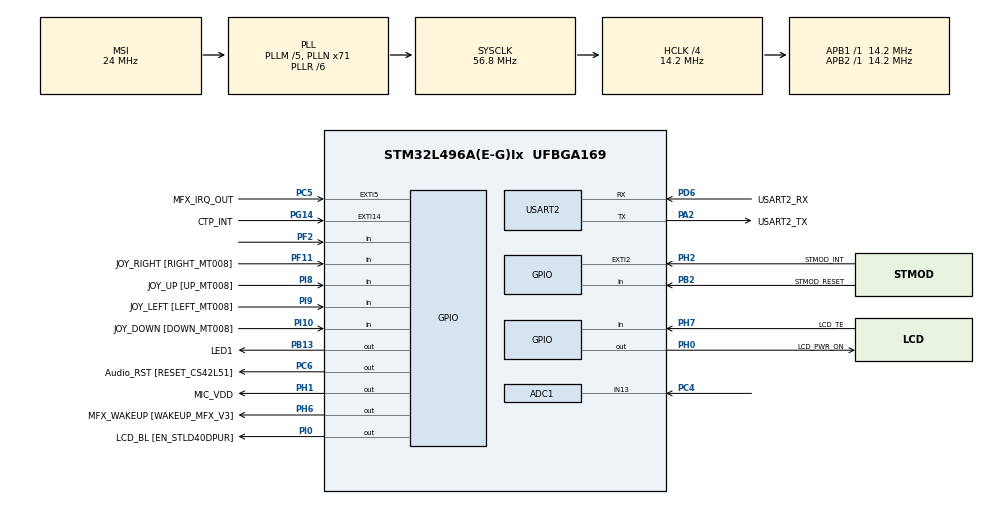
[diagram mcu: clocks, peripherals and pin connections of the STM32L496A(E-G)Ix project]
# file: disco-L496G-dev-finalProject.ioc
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ADC1.Channel-0\#ChannelRegularConversion=ADC_CHANNEL_13
ADC1.NbrOfConversionFlag=1
ADC1.OffsetNumber-0\#ChannelRegularConversion=ADC_OFFSET_NONE
ADC1.Rank-0\#ChannelRegularConversion=1
ADC1.SamplingTime-0\#ChannelRegularConversion=ADC_SAMPLETIME_2CYCLES_5
ADC1.master=1
Mcu.Family=STM32L4
Mcu.Name=STM32L496A(E-G)Ix
Mcu.Package=UFBGA169
NVIC.PriorityGroup=NVIC_PRIORITYGROUP_4
PA0.GPIO_Label=STMOD_PWM
PA0.Signal=SYS_WKUP1
PA1.GPIO_Label=ARD_A4
PA1.Signal=ADCx_IN6
PA10.GPIO_Label=USB_OTGFS_ID
PA10.Signal=USB_OTG_FS_ID
PA11.GPIO_Label=USB_OTGFS_DM
PA11.Signal=USB_OTG_FS_DM
PA12.GPIO_Label=USB_OTGFS_DP
PA12.Signal=USB_OTG_FS_DP
PA13\ (JTMS/SWDIO).GPIO_Label=SWDIO
PA13\ (JTMS/SWDIO).Signal=SYS_JTMS-SWDIO
PA14\ (JTCK/SWCLK).GPIO_Label=SWCLK
PA14\ (JTCK/SWCLK).Signal=SYS_JTCK-SWCLK
PA15\ (JTDI).GPIO_Label=ARD_D10
PA15\ (JTDI).Signal=SPI1_NSS
PA2.GPIO_Label=USART2_TX
PA2.Mode=Asynchronous
PA2.Signal=USART2_TX
PA3.GPIO_Label=QSPI_CLK [MX25R6435FM2IL0_SCLK]
PA3.Signal=QUADSPI_CLK
PA4.GPIO_Label=STMOD_ADC
PA4.Signal=ADCx_IN9
PA5.GPIO_Label=ARD_D13
PA5.Signal=SPI1_SCK
PA6.GPIO_Label=QSPI_BK1_IO3 [MX25R6435FM2IL0_SIO3]
PA6.Signal=QUADSPI_BK1_IO3
PA7.GPIO_Label=QSPI_BK1_IO2 [MX25R6435FM2IL0_SIO2]
PA7.Signal=QUADSPI_BK1_IO2
PA8.GPIO_Label=DCMI_CLK
PA8.Signal=LPTIM2_OUT
PA9.GPIO_Label=USB_OTGFS_VBUS
PA9.Signal=USB_OTG_FS_VBUS
PB0.GPIO_Label=QSPI_BK1_IO1 [MX25R6435FM2IL0_SIO1]
PB0.Signal=QUADSPI_BK1_IO1
PB1.GPIO_Label=QSPI_BK1_IO0 [MX25R6435FM2IL0_SIO0]
PB1.Signal=QUADSPI_BK1_IO0
PB10.GPIO_Label=SAI1_CKA [SLCK_CS42L51]
PB10.Signal=SAI1_SCK_A
PB11.GPIO_Label=QSPI_BK1_NCS [MX25R6435FM2IL0_CS]
PB11.Signal=QUADSPI_BK1_NCS
PB12.GPIO_Label=DFDATIN1
PB12.Signal=S_DATAIN1DFSDM1
PB13.GPIO_Label=LED1
PB13.GPIO_ModeDefaultOutputPP=GPIO_MODE_OUTPUT_OD
PB13.GPIO_PuPd=GPIO_NOPULL
PB13.Signal=GPIO_Output
PB14.GPIO_Label=I2C2_SDA [CS42L51_SDA]
PB14.Signal=I2C2_SDA
PB15.GPIO_Label=SPI2_MOSI
PB15.Signal=SPI2_MOSI
PB2.GPIO_Label=STMOD_RESET
PB2.Signal=GPIO_Input
PB3\ (JTDO/TRACESWO).GPIO_Label=SWO
PB3\ (JTDO/TRACESWO).Signal=SYS_JTDO-SWO
PB4\ (NJTRST).GPIO_Label=ARD_D12
PB4\ (NJTRST).Signal=SPI1_MISO
PB5.GPIO_Label=ARD_D11
PB5.Signal=SPI1_MOSI
PB6.GPIO_Label=USART1_TX
PB6.Signal=USART1_TX
PB7.GPIO_Label=I2C1_SDA
PB7.Signal=I2C1_SDA
PB8.GPIO_Label=I2C1_SCL
PB8.Signal=I2C1_SCL
PB9.GPIO_Label=ARD_D5
PB9.Signal=S_TIM4_CH4
PC0.GPIO_Label=ARD_A5
PC0.Signal=ADCx_IN1
PC1.Signal=ADCx_IN2
PC10.GPIO_Label=uSD_D2
PC10.Signal=SDMMC1_D2
PC11.GPIO_Label=uSD_D3
PC11.Signal=SDMMC1_D3
PC12.GPIO_Label=uSD_CLK
PC12.Signal=SDMMC1_CK
PC13.GPIO_Label=JOY_SEL [Selection_MT008]
PC13.Signal=SYS_WKUP2
PC14-OSC32_IN\ (PC14).Signal=RCC_OSC32_IN
PC15-OSC32_OUT\ (PC15).Signal=RCC_OSC32_OUT
PC2.GPIO_Label=DF_CKOUT
PC2.Signal=S_CKOUTDFSDM1
PC3.GPIO_Label=ARD_A2
PC3.Signal=ADCx_IN4
PC4.Signal=ADCx_IN13
PC5.GPIO_Label=MFX_IRQ_OUT
PC5.Signal=GPXTI5
PC6.GPIO_Label=Audio_RST [RESET_CS42L51]
PC6.Signal=GPIO_Output
PC7.GPIO_Label=DATIN3 [DOUT_MP34DT01TR]
PC7.Signal=S_DATAIN3DFSDM1
PC8.GPIO_Label=uSD_D0
PC8.Signal=SDMMC1_D0
PC9.GPIO_Label=uSD_D1
PC9.Signal=SDMMC1_D1
PD0.GPIO_Label=D2 [D2_ IS66WV51216EBLL]
PD0.Signal=FMC_D2_DA2
PD1.GPIO_Label=D3 [D3_IS66WV51216EBLL]
PD1.Signal=FMC_D3_DA3
PD10.GPIO_Label=D15 [D15_IS66WV51216EBLL]
PD10.Signal=FMC_D15_DA15
PD11.GPIO_Label=PSRAM_A16 [A16_IS66WV51216EBLL]
PD11.Signal=FMC_A16_CLE
PD12.GPIO_Label=PSRAM_A17 [A17_IS66WV51216EBLL]
PD12.Signal=FMC_A17_ALE
PD13.GPIO_Label=PSRAM_A18_LCD_RS [A18_IS66WV51216EBLL]
PD13.Signal=FMC_A18
PD14.GPIO_Label=D0 [D0_IS66WV51216EBLL]
PD14.Signal=FMC_D0_DA0
PD15.GPIO_Label=D1 [D1_IS66WV51216EBLL]
PD15.Signal=FMC_D1_DA1
PD2.GPIO_Label=uSD_CMD
PD2.Signal=SDMMC1_CMD
PD4.GPIO_Label=OE [OE_IS66WV51216EBLL]
PD4.Signal=FMC_NOE
PD5.GPIO_Label=WE [WE_IS66WV51216EBLL]
PD5.Signal=FMC_NWE
PD6.GPIO_Label=USART2_RX
PD6.Mode=Asynchronous
PD6.Signal=USART2_RX
PD7.GPIO_Label=LCD_NE
PD7.Signal=FMC_NE1
PD8.GPIO_Label=D13 [D13_IS66WV51216EBLL]
PD8.Signal=FMC_D13_DA13
PD9.GPIO_Label=D14 [D14_IS66WV51216EBLL]
PD9.Signal=FMC_D14_DA14
PE0.GPIO_Label=PSRAM_NBL0 [LB_IS66WV51216EBLL]
PE0.Signal=FMC_NBL0
PE1.GPIO_Label=PSRAM_NBL1 [UB_IS66WV51216EBLL]
PE1.Signal=FMC_NBL1
PE10.GPIO_Label=D7 [D7_IS66WV51216EBLL]
PE10.Signal=FMC_D7_DA7
PE11.GPIO_Label=D8  [D8_IS66WV51216EBLL]
PE11.Signal=FMC_D8_DA8
PE12.GPIO_Label=D9 [D9_IS66WV51216EBLL]
PE12.Signal=FMC_D9_DA9
PE13.GPIO_Label=D10 [D10_IS66WV51216EBLL]
PE13.Signal=FMC_D10_DA10
PE14.GPIO_Label=D11 [D11_IS66WV51216EBLL]
PE14.Signal=FMC_D11_DA11
PE15.GPIO_Label=D12 [D12_IS66WV51216EBLL]
PE15.Signal=FMC_D12_DA12
PE2.GPIO_Label=SAI1_MCKA [MCLK_CS42L51]
PE2.Signal=SAI1_MCLK_A
PE3.GPIO_Label=SAI1_SDB [SDOUT_CS42L51]
PE3.Signal=SAI1_SD_B
PE4.GPIO_Label=SAI1_FSA [LRCK_CS42L51]]
PE4.Signal=SAI1_FS_A
PE5.GPIO_Label=DCMI_D6
PE5.Signal=DCMI_D6
PE6.GPIO_Label=SAI1_SDA [SDIN_CS42L51]
PE6.Signal=SAI1_SD_A
PE7.GPIO_Label=D4 [D4_IS66WV51216EBLL]
PE7.Signal=FMC_D4_DA4
PE8.GPIO_Label=D5 [D5_IS66WV51216EBLL]
PE8.Signal=FMC_D5_DA5
PE9.GPIO_Label=D6 [D6_IS66WV51216EBLL]
PE9.Signal=FMC_D6_DA6
PF0.GPIO_Label=PSRAM_A0 [A0_IS66WV51216EBLL]
PF0.Signal=FMC_A0
PF1.GPIO_Label=PSRAM_A1 [A1_IS66WV51216EBLL]
PF1.Signal=FMC_A1
PF10.GPIO_Label=ARD_A3
PF10.Signal=ADC3_IN13
PF11.GPIO_Label=JOY_RIGHT [RIGHT_MT008]
PF11.GPIO_PuPd=GPIO_PULLDOWN
PF11.Signal=GPIO_Input
PF12.GPIO_Label=PSRAM_A6 [A6_IS66WV51216EBLL]
PF12.Signal=FMC_A6
PF13.GPIO_Label=PSRAM_A7 [A7_IS66WV51216EBLL]
PF13.Signal=FMC_A7
PF14.GPIO_Label=PSRAM_A8 [A8_IS66WV51216EBLL]
PF14.Signal=FMC_A8
PF15.GPIO_Label=PSRAM_A9 [A9_IS66WV51216EBLL]
PF15.Signal=FMC_A9
PF2.Signal=GPIO_Input
PF3.GPIO_Label=PSRAM_A3 [A3_IS66WV51216EBLL]
PF3.Signal=FMC_A3
PF4.GPIO_Label=PSRAM_A4 [A4_IS66WV51216EBLL]
PF4.Signal=FMC_A4
PF5.GPIO_Label=PSRAM_A5 [A5_IS66WV51216EBLL]
PF5.Signal=FMC_A5
PG0.GPIO_Label=PSRAM_A10 [A10_IS66WV51216EBLL]
PG0.Signal=FMC_A10
PG1.GPIO_Label=PSRAM_A11 [A11_IS66WV51216EBLL]
PG1.Signal=FMC_A11
PG10.GPIO_Label=UART1_RX [STMOD+_UART]
PG10.Signal=USART1_RX
PG11.GPIO_Label=UART1_CTS [STMOD+_UART]
PG11.Signal=USART1_CTS
PG12.GPIO_Label=UART1_RTS [STMOD+_UART]
PG12.Signal=USART1_RTS
PG14.GPIO_Label=CTP_INT
PG14.Signal=GPXTI14
PG2.GPIO_Label=PSRAM_A12 [A12_IS66WV51216EBLL]
PG2.Signal=FMC_A12
PG3.GPIO_Label=PSRAM_A13 [A13_IS66WV51216EBLL]
PG3.Signal=FMC_A13
PG4.GPIO_Label=PSRAM_A14 [A14_IS66WV51216EBLL]
PG4.Signal=FMC_A14
PG5.GPIO_Label=PSRAM_A15 [A15_IS66WV51216EBLL]
PG5.Signal=FMC_A15
PG7.GPIO_Label=ARD_D1
PG7.Signal=LPUART1_TX
PG8.GPIO_Label=ARD_D0
PG8.Signal=LPUART1_RX
PG9.GPIO_Label=PSRAM_NE [CS1_IS66WV51216EBLL]
PG9.Signal=FMC_NE2
PH0-OSC_IN\ (PH0).GPIO_Label=LCD_PWR_ON
PH0-OSC_IN\ (PH0).Signal=GPIO_Output
PH1-OSC_OUT\ (PH1).GPIO_Label=MIC_VDD
PH1-OSC_OUT\ (PH1).Signal=GPIO_Output
PH10.GPIO_Label=DCMI_D1
PH10.Signal=DCMI_D1
PH11.GPIO_Label=DCMI_D2
PH11.Signal=DCMI_D2
PH12.GPIO_Label=DCMI_D3
PH12.Signal=DCMI_D3
PH13.GPIO_Label=ARD_D9
PH13.Signal=TIM8_CH1N
PH14.GPIO_Label=DCMI_D4
PH14.Signal=DCMI_D4
PH15.GPIO_Label=ARD_D3
PH15.Signal=TIM8_CH3N
PH2.GPIO_Label=STMOD_INT
PH2.Signal=GPXTI2
PH4.GPIO_Label=I2C2_SCL [SCL_CS42L51]
PH4.Signal=I2C2_SCL
PH5.GPIO_Label=DCMI_PIXCK
PH5.Signal=DCMI_PIXCLK
PH6.GPIO_Label=MFX_WAKEUP [WAKEUP_MFX_V3]
PH6.Signal=GPIO_Output
PH7.GPIO_Label=LCD_TE
PH7.Signal=GPIO_Input
PH8.GPIO_Label=DCMI_HSYNC
PH8.Signal=DCMI_HSYNC
PH9.GPIO_Label=DCMI_D0
PH9.Signal=DCMI_D0
PI0.GPIO_Label=LCD_BL [EN_STLD40DPUR]
PI0.Signal=GPIO_Output
PI1.GPIO_Label=SPI2_CLK [STMOD+_SPI]
PI1.Signal=SPI2_SCK
PI10.GPIO_Label=JOY_DOWN [DOWN_MT008]
PI10.GPIO_PuPd=GPIO_PULLDOWN
PI10.Signal=GPIO_Input
PI2.GPIO_Label=SPI2_MISO [STMOD+_SPI]
PI2.Signal=SPI2_MISO
PI4.GPIO_Label=DCMI_D5
PI4.Signal=DCMI_D5
PI5.GPIO_Label=DCMI_VSYNC
PI5.Signal=DCMI_VSYNC
PI6.GPIO_Label=ARD_D6
PI6.Signal=S_TIM8_CH2
PI7.GPIO_Label=DCMI_D7
PI7.Signal=DCMI_D7
PI8.GPIO_Label=JOY_UP [UP_MT008]
PI8.GPIO_PuPd=GPIO_PULLDOWN
PI8.Signal=GPIO_Input
PI9.GPIO_Label=JOY_LEFT [LEFT_MT008]
PI9.GPIO_PuPd=GPIO_PULLDOWN
PI9.Signal=GPIO_Input
ProjectManager.HeapSize=0x200
ProjectManager.StackSize=0x400
ProjectManager.TargetToolchain=STM32CubeIDE
RCC.ADCFreq_Value=48000000
RCC.AHBCLKDivider=RCC_SYSCLK_DIV4
RCC.AHBFreq_Value=14200000
RCC.APB1Freq_Value=14200000
RCC.APB1TimFreq_Value=14200000
RCC.APB2Freq_Value=14200000
RCC.APB2TimFreq_Value=14200000
RCC.CortexFreq_Value=14200000
RCC.HCLKFreq_Value=14200000
RCC.HSE_VALUE=8000000
RCC.HSI48_VALUE=48000000
RCC.HSI_VALUE=16000000
RCC.LSE_VALUE=32768
RCC.MSIClockRange=RCC_MSIRANGE_9
RCC.MSI_VALUE=24000000
RCC.PLLM=5
RCC.PLLN=71
RCC.PLLR=RCC_PLLR_DIV6
RCC.PLLSAI1N=20
RCC.SYSCLKFreq_VALUE=56800000
RCC.SYSCLKSource=RCC_SYSCLKSOURCE_PLLCLK
RCC.USBFreq_Value=48000000
RCC.VCOOutputFreq_Value=340800000
SH.ADCx_IN1.0=ADC2_IN1
SH.ADCx_IN13.0=ADC1_IN13,IN13-Single-Ended
SH.ADCx_IN2.0=ADC2_IN2
SH.ADCx_IN4.0=ADC1_IN4
SH.ADCx_IN6.0=ADC2_IN6
SH.ADCx_IN9.0=ADC2_IN9
SH.FMC_A0.0=FMC_A0
SH.FMC_A1.0=FMC_A1
SH.FMC_A10.0=FMC_A10
SH.FMC_A11.0=FMC_A11
SH.FMC_A12.0=FMC_A12
SH.FMC_A13.0=FMC_A13
SH.FMC_A14.0=FMC_A14
SH.FMC_A15.0=FMC_A15
SH.FMC_A16_CLE.0=FMC_A16
SH.FMC_A17_ALE.0=FMC_A17
SH.FMC_A18.0=FMC_A18
SH.FMC_A3.0=FMC_A3
SH.FMC_A4.0=FMC_A4
SH.FMC_A5.0=FMC_A5
SH.FMC_A6.0=FMC_A6
SH.FMC_A7.0=FMC_A7
SH.FMC_A8.0=FMC_A8
SH.FMC_A9.0=FMC_A9
SH.FMC_D0_DA0.0=FMC_D0
SH.FMC_D10_DA10.0=FMC_D10
SH.FMC_D11_DA11.0=FMC_D11
SH.FMC_D12_DA12.0=FMC_D12
SH.FMC_D13_DA13.0=FMC_D13
SH.FMC_D14_DA14.0=FMC_D14
SH.FMC_D15_DA15.0=FMC_D15
SH.FMC_D1_DA1.0=FMC_D1
SH.FMC_D2_DA2.0=FMC_D2
SH.FMC_D3_DA3.0=FMC_D3
SH.FMC_D4_DA4.0=FMC_D4
SH.FMC_D5_DA5.0=FMC_D5
SH.FMC_D6_DA6.0=FMC_D6
SH.FMC_D7_DA7.0=FMC_D7
SH.FMC_D8_DA8.0=FMC_D8
SH.FMC_D9_DA9.0=FMC_D9
SH.FMC_NBL0.0=FMC_NBL0
SH.FMC_NBL1.0=FMC_NBL1
SH.FMC_NOE.0=FMC_NOE
SH.FMC_NWE.0=FMC_NWE
SH.S_CKOUTDFSDM1.0=DFSDM1_CKOUT
SH.S_DATAIN1DFSDM1.0=DFSDM1_DATIN1
SH.S_DATAIN3DFSDM1.0=DFSDM1_DATIN3
SH.S_TIM4_CH4.0=TIM4_CH4
SH.S_TIM8_CH2.0=TIM8_CH2
USART2.VirtualMode-Asynchronous=VM_ASYNC
board=STM32L496G-DISCO

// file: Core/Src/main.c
/* USER CODE BEGIN Header */
/**
  ******************************************************************************
  * @file           : main.c
  * @brief          : Main program body
  ******************************************************************************
  * @attention
  *
  * Copyright (c) 2022 STMicroelectronics.
  * All rights reserved.
  *
  * This software is licensed under terms that can be found in the LICENSE file
  * in the root directory of this software component.
  * If no LICENSE file comes with this software, it is provided AS-IS.
  *
  ******************************************************************************
  */
/* USER CODE END Header */
#include "main.h"
#include "stdio.h"

ADC_HandleTypeDef hadc1;

UART_HandleTypeDef huart2;

void SystemClock_Config(void);
static void MX_GPIO_Init(void);
static void MX_USART2_UART_Init(void);
static void MX_ADC1_Init(void);

/* USER CODE BEGIN 0 */

int _write(int file, char *ptr, int len)
{

	HAL_UART_Transmit(&huart2, (uint8_t*)ptr, len, HAL_MAX_DELAY);
	return len;
}

/* USER CODE END 0 */

int main(void)
{

  /* MCU Configuration--------------------------------------------------------*/

  /* Reset of all peripherals, Initializes the Flash interface and the Systick. */
  HAL_Init();

  /* Configure the system clock */
  SystemClock_Config();

  /* Initialize all configured peripherals */
  MX_GPIO_Init();
  MX_USART2_UART_Init();
  MX_ADC1_Init();

  /* Infinite loop */
  /* USER CODE BEGIN WHILE */
  while (1)
  {

	 //printf("working");

	  // c
	  HAL_ADC_Start(&hadc1);
	  HAL_ADC_PollForConversion(&hadc1, HAL_MAX_DELAY);

	  uint32_t value= HAL_ADC_GetValue(&hadc1);
	  float voltage = (5.0 * value) / (4096.0);
	  printf("Voltage Value Read From Knob: %f \r\n", voltage);

    /* USER CODE END WHILE */

  }
}

void SystemClock_Config(void)
{
  RCC_OscInitTypeDef RCC_OscInitStruct = {0};
  RCC_ClkInitTypeDef RCC_ClkInitStruct = {0};

  /** Configure the main internal regulator output voltage
  */
  if (HAL_PWREx_ControlVoltageScaling(PWR_REGULATOR_VOLTAGE_SCALE1) != HAL_OK)
  {
    Error_Handler();
  }

  /** Initializes the RCC Oscillators according to the specified parameters
  * in the RCC_OscInitTypeDef structure.
  */
  RCC_OscInitStruct.OscillatorType = RCC_OSCILLATORTYPE_MSI;
  RCC_OscInitStruct.MSIState = RCC_MSI_ON;
  RCC_OscInitStruct.MSICalibrationValue = 0;
  RCC_OscInitStruct.MSIClockRange = RCC_MSIRANGE_9;
  RCC_OscInitStruct.PLL.PLLState = RCC_PLL_ON;
  RCC_OscInitStruct.PLL.PLLSource = RCC_PLLSOURCE_MSI;
  RCC_OscInitStruct.PLL.PLLM = 5;
  RCC_OscInitStruct.PLL.PLLN = 71;
  RCC_OscInitStruct.PLL.PLLP = RCC_PLLP_DIV2;
  RCC_OscInitStruct.PLL.PLLQ = RCC_PLLQ_DIV2;
  RCC_OscInitStruct.PLL.PLLR = RCC_PLLR_DIV6;
  if (HAL_RCC_OscConfig(&RCC_OscInitStruct) != HAL_OK)
  {
    Error_Handler();
  }

  /** Initializes the CPU, AHB and APB buses clocks
  */
  RCC_ClkInitStruct.ClockType = RCC_CLOCKTYPE_HCLK|RCC_CLOCKTYPE_SYSCLK
                              |RCC_CLOCKTYPE_PCLK1|RCC_CLOCKTYPE_PCLK2;
  RCC_ClkInitStruct.SYSCLKSource = RCC_SYSCLKSOURCE_PLLCLK;
  RCC_ClkInitStruct.AHBCLKDivider = RCC_SYSCLK_DIV4;
  RCC_ClkInitStruct.APB1CLKDivider = RCC_HCLK_DIV1;
  RCC_ClkInitStruct.APB2CLKDivider = RCC_HCLK_DIV1;

  if (HAL_RCC_ClockConfig(&RCC_ClkInitStruct, FLASH_LATENCY_0) != HAL_OK)
  {
    Error_Handler();
  }
}

static void MX_ADC1_Init(void)
{

  ADC_MultiModeTypeDef multimode = {0};
  ADC_ChannelConfTypeDef sConfig = {0};

  /** Common config
  */
  hadc1.Instance = ADC1;
  hadc1.Init.ClockPrescaler = ADC_CLOCK_ASYNC_DIV1;
  hadc1.Init.Resolution = ADC_RESOLUTION_12B;
  hadc1.Init.DataAlign = ADC_DATAALIGN_RIGHT;
  hadc1.Init.ScanConvMode = ADC_SCAN_DISABLE;
  hadc1.Init.EOCSelection = ADC_EOC_SINGLE_CONV;
  hadc1.Init.LowPowerAutoWait = DISABLE;
  hadc1.Init.ContinuousConvMode = DISABLE;
  hadc1.Init.NbrOfConversion = 1;
  hadc1.Init.DiscontinuousConvMode = DISABLE;
  hadc1.Init.ExternalTrigConv = ADC_SOFTWARE_START;
  hadc1.Init.ExternalTrigConvEdge = ADC_EXTERNALTRIGCONVEDGE_NONE;
  hadc1.Init.DMAContinuousRequests = DISABLE;
  hadc1.Init.Overrun = ADC_OVR_DATA_PRESERVED;
  hadc1.Init.OversamplingMode = DISABLE;
  if (HAL_ADC_Init(&hadc1) != HAL_OK)
  {
    Error_Handler();
  }

  /** Configure the ADC multi-mode
  */
  multimode.Mode = ADC_MODE_INDEPENDENT;
  if (HAL_ADCEx_MultiModeConfigChannel(&hadc1, &multimode) != HAL_OK)
  {
    Error_Handler();
  }

  /** Configure Regular Channel
  */
  sConfig.Channel = ADC_CHANNEL_13;
  sConfig.Rank = ADC_REGULAR_RANK_1;
  sConfig.SamplingTime = ADC_SAMPLETIME_2CYCLES_5;
  sConfig.SingleDiff = ADC_SINGLE_ENDED;
  sConfig.OffsetNumber = ADC_OFFSET_NONE;
  sConfig.Offset = 0;
  if (HAL_ADC_ConfigChannel(&hadc1, &sConfig) != HAL_OK)
  {
    Error_Handler();
  }

}

static void MX_USART2_UART_Init(void)
{

  huart2.Instance = USART2;
  huart2.Init.BaudRate = 115200;
  huart2.Init.WordLength = UART_WORDLENGTH_8B;
  huart2.Init.StopBits = UART_STOPBITS_1;
  huart2.Init.Parity = UART_PARITY_NONE;
  huart2.Init.Mode = UART_MODE_TX_RX;
  huart2.Init.HwFlowCtl = UART_HWCONTROL_NONE;
  huart2.Init.OverSampling = UART_OVERSAMPLING_16;
  huart2.Init.OneBitSampling = UART_ONE_BIT_SAMPLE_DISABLE;
  huart2.AdvancedInit.AdvFeatureInit = UART_ADVFEATURE_NO_INIT;
  if (HAL_UART_Init(&huart2) != HAL_OK)
  {
    Error_Handler();
  }

}

static void MX_GPIO_Init(void)
{
  GPIO_InitTypeDef GPIO_InitStruct = {0};

  /* GPIO Ports Clock Enable */
  __HAL_RCC_GPIOI_CLK_ENABLE();
  __HAL_RCC_GPIOH_CLK_ENABLE();
  __HAL_RCC_GPIOE_CLK_ENABLE();
  __HAL_RCC_GPIOB_CLK_ENABLE();
  __HAL_RCC_GPIOA_CLK_ENABLE();
  __HAL_RCC_GPIOG_CLK_ENABLE();
  HAL_PWREx_EnableVddIO2();
  __HAL_RCC_GPIOD_CLK_ENABLE();
  __HAL_RCC_GPIOC_CLK_ENABLE();
  __HAL_RCC_GPIOF_CLK_ENABLE();

  /*Configure GPIO pin Output Level */
  HAL_GPIO_WritePin(LCD_BL_GPIO_Port, LCD_BL_Pin, GPIO_PIN_RESET);

  /*Configure GPIO pin Output Level */
  HAL_GPIO_WritePin(GPIOH, MFX_WAKEUP_Pin|LCD_PWR_ON_Pin|MIC_VDD_Pin, GPIO_PIN_RESET);

  /*Configure GPIO pin Output Level */
  HAL_GPIO_WritePin(Audio_RST_GPIO_Port, Audio_RST_Pin, GPIO_PIN_RESET);

  /*Configure GPIO pin Output Level */
  HAL_GPIO_WritePin(LED1_GPIO_Port, LED1_Pin, GPIO_PIN_RESET);

  /*Configure GPIO pins : JOY_DOWN_Pin JOY_LEFT_Pin JOY_UP_Pin */
  GPIO_InitStruct.Pin = JOY_DOWN_Pin|JOY_LEFT_Pin|JOY_UP_Pin;
  GPIO_InitStruct.Mode = GPIO_MODE_INPUT;
  GPIO_InitStruct.Pull = GPIO_PULLDOWN;
  HAL_GPIO_Init(GPIOI, &GPIO_InitStruct);

  /*Configure GPIO pin : STMOD_INT_Pin */
  GPIO_InitStruct.Pin = STMOD_INT_Pin;
  GPIO_InitStruct.Mode = GPIO_MODE_IT_RISING;
  GPIO_InitStruct.Pull = GPIO_NOPULL;
  HAL_GPIO_Init(STMOD_INT_GPIO_Port, &GPIO_InitStruct);

  /*Configure GPIO pins : PSRAM_NBL0_Pin PSRAM_NBL1_Pin D7_Pin D6_Pin
                           D12_Pin D5_Pin D11_Pin D4_Pin
                           D10_Pin D9_Pin D8_Pin */
  GPIO_InitStruct.Pin = PSRAM_NBL0_Pin|PSRAM_NBL1_Pin|D7_Pin|D6_Pin
                          |D12_Pin|D5_Pin|D11_Pin|D4_Pin
                          |D10_Pin|D9_Pin|D8_Pin;
  GPIO_InitStruct.Mode = GPIO_MODE_AF_PP;
  GPIO_InitStruct.Pull = GPIO_NOPULL;
  GPIO_InitStruct.Speed = GPIO_SPEED_FREQ_VERY_HIGH;
  GPIO_InitStruct.Alternate = GPIO_AF12_FMC;
  HAL_GPIO_Init(GPIOE, &GPIO_InitStruct);

  /*Configure GPIO pins : ARD_D12_Pin ARD_D11_Pin */
  GPIO_InitStruct.Pin = ARD_D12_Pin|ARD_D11_Pin;
  GPIO_InitStruct.Mode = GPIO_MODE_AF_PP;
  GPIO_InitStruct.Pull = GPIO_NOPULL;
  GPIO_InitStruct.Speed = GPIO_SPEED_FREQ_VERY_HIGH;
  GPIO_InitStruct.Alternate = GPIO_AF5_SPI1;
  HAL_GPIO_Init(GPIOB, &GPIO_InitStruct);

  /*Configure GPIO pins : ARD_D10_Pin ARD_D13_Pin */
  GPIO_InitStruct.Pin = ARD_D10_Pin|ARD_D13_Pin;
  GPIO_InitStruct.Mode = GPIO_MODE_AF_PP;
  GPIO_InitStruct.Pull = GPIO_NOPULL;
  GPIO_InitStruct.Speed = GPIO_SPEED_FREQ_VERY_HIGH;
  GPIO_InitStruct.Alternate = GPIO_AF5_SPI1;
  HAL_GPIO_Init(GPIOA, &GPIO_InitStruct);

  /*Configure GPIO pin : LCD_BL_Pin */
  GPIO_InitStruct.Pin = LCD_BL_Pin;
  GPIO_InitStruct.Mode = GPIO_MODE_OUTPUT_PP;
  GPIO_InitStruct.Pull = GPIO_NOPULL;
  GPIO_InitStruct.Speed = GPIO_SPEED_FREQ_LOW;
  HAL_GPIO_Init(LCD_BL_GPIO_Port, &GPIO_InitStruct);

  /*Configure GPIO pins : DCMI_D4_Pin DCMI_D3_Pin DCMI_D0_Pin DCMI_PIXCK_Pin
                           DCMI_D1_Pin DCMI_D2_Pin DCMI_HSYNC_Pin */
  GPIO_InitStruct.Pin = DCMI_D4_Pin|DCMI_D3_Pin|DCMI_D0_Pin|DCMI_PIXCK_Pin
                          |DCMI_D1_Pin|DCMI_D2_Pin|DCMI_HSYNC_Pin;
  GPIO_InitStruct.Mode = GPIO_MODE_AF_PP;
  GPIO_InitStruct.Pull = GPIO_NOPULL;
  GPIO_InitStruct.Speed = GPIO_SPEED_FREQ_LOW;
  GPIO_InitStruct.Alternate = GPIO_AF10_DCMI;
  HAL_GPIO_Init(GPIOH, &GPIO_InitStruct);

  /*Configure GPIO pins : DCMI_D7_Pin DCMI_D5_Pin DCMI_VSYNC_Pin */
  GPIO_InitStruct.Pin = DCMI_D7_Pin|DCMI_D5_Pin|DCMI_VSYNC_Pin;
  GPIO_InitStruct.Mode = GPIO_MODE_AF_PP;
  GPIO_InitStruct.Pull = GPIO_NOPULL;
  GPIO_InitStruct.Speed = GPIO_SPEED_FREQ_LOW;
  GPIO_InitStruct.Alternate = GPIO_AF10_DCMI;
  HAL_GPIO_Init(GPIOI, &GPIO_InitStruct);

  /*Configure GPIO pins : PSRAM_NE_Pin PSRAM_A11_Pin PSRAM_A10_Pin PSRAM_A15_Pin
                           PSRAM_A14_Pin PSRAM_A13_Pin PSRAM_A12_Pin */
  GPIO_InitStruct.Pin = PSRAM_NE_Pin|PSRAM_A11_Pin|PSRAM_A10_Pin|PSRAM_A15_Pin
                          |PSRAM_A14_Pin|PSRAM_A13_Pin|PSRAM_A12_Pin;
  GPIO_InitStruct.Mode = GPIO_MODE_AF_PP;
  GPIO_InitStruct.Pull = GPIO_NOPULL;
  GPIO_InitStruct.Speed = GPIO_SPEED_FREQ_VERY_HIGH;
  GPIO_InitStruct.Alternate = GPIO_AF12_FMC;
  HAL_GPIO_Init(GPIOG, &GPIO_InitStruct);

  /*Configure GPIO pins : D2_Pin OE_Pin D3_Pin WE_Pin
                           LCD_NE_Pin D1_Pin D15_Pin D0_Pin
                           PSRAM_A17_Pin PSRAM_A16_Pin PSRAM_A18_LCD_RS_Pin D14_Pin
                           D13_Pin */
  GPIO_InitStruct.Pin = D2_Pin|OE_Pin|D3_Pin|WE_Pin
                          |LCD_NE_Pin|D1_Pin|D15_Pin|D0_Pin
                          |PSRAM_A17_Pin|PSRAM_A16_Pin|PSRAM_A18_LCD_RS_Pin|D14_Pin
                          |D13_Pin;
  GPIO_InitStruct.Mode = GPIO_MODE_AF_PP;
  GPIO_InitStruct.Pull = GPIO_NOPULL;
  GPIO_InitStruct.Speed = GPIO_SPEED_FREQ_VERY_HIGH;
  GPIO_InitStruct.Alternate = GPIO_AF12_FMC;
  HAL_GPIO_Init(GPIOD, &GPIO_InitStruct);

  /*Configure GPIO pin : ARD_D6_Pin */
  GPIO_InitStruct.Pin = ARD_D6_Pin;
  GPIO_InitStruct.Mode = GPIO_MODE_AF_PP;
  GPIO_InitStruct.Pull = GPIO_NOPULL;
  GPIO_InitStruct.Speed = GPIO_SPEED_FREQ_LOW;
  GPIO_InitStruct.Alternate = GPIO_AF3_TIM8;
  HAL_GPIO_Init(ARD_D6_GPIO_Port, &GPIO_InitStruct);

  /*Configure GPIO pins : SPI2_MISO_Pin SPI2_CLK_Pin */
  GPIO_InitStruct.Pin = SPI2_MISO_Pin|SPI2_CLK_Pin;
  GPIO_InitStruct.Mode = GPIO_MODE_AF_PP;
  GPIO_InitStruct.Pull = GPIO_NOPULL;
  GPIO_InitStruct.Speed = GPIO_SPEED_FREQ_VERY_HIGH;
  GPIO_InitStruct.Alternate = GPIO_AF5_SPI2;
  HAL_GPIO_Init(GPIOI, &GPIO_InitStruct);

  /*Configure GPIO pins : ARD_D3_Pin ARD_D9_Pin */
  GPIO_InitStruct.Pin = ARD_D3_Pin|ARD_D9_Pin;
  GPIO_InitStruct.Mode = GPIO_MODE_AF_PP;
  GPIO_InitStruct.Pull = GPIO_NOPULL;
  GPIO_InitStruct.Speed = GPIO_SPEED_FREQ_LOW;
  GPIO_InitStruct.Alternate = GPIO_AF3_TIM8;
  HAL_GPIO_Init(GPIOH, &GPIO_InitStruct);

  /*Configure GPIO pins : I2C1_SCL_Pin I2C1_SDA_Pin */
  GPIO_InitStruct.Pin = I2C1_SCL_Pin|I2C1_SDA_Pin;
  GPIO_InitStruct.Mode = GPIO_MODE_AF_OD;
  GPIO_InitStruct.Pull = GPIO_NOPULL;
  GPIO_InitStruct.Speed = GPIO_SPEED_FREQ_VERY_HIGH;
  GPIO_InitStruct.Alternate = GPIO_AF4_I2C1;
  HAL_GPIO_Init(GPIOB, &GPIO_InitStruct);

  /*Configure GPIO pin : USART1_TX_Pin */
  GPIO_InitStruct.Pin = USART1_TX_Pin;
  GPIO_InitStruct.Mode = GPIO_MODE_AF_PP;
  GPIO_InitStruct.Pull = GPIO_NOPULL;
  GPIO_InitStruct.Speed = GPIO_SPEED_FREQ_VERY_HIGH;
  GPIO_InitStruct.Alternate = GPIO_AF7_USART1;
  HAL_GPIO_Init(USART1_TX_GPIO_Port, &GPIO_InitStruct);

  /*Configure GPIO pins : SAI1_FSA_Pin SAI1_SDB_Pin SAI1_MCKA_Pin SAI1_SDA_Pin */
  GPIO_InitStruct.Pin = SAI1_FSA_Pin|SAI1_SDB_Pin|SAI1_MCKA_Pin|SAI1_SDA_Pin;
  GPIO_InitStruct.Mode = GPIO_MODE_AF_PP;
  GPIO_InitStruct.Pull = GPIO_NOPULL;
  GPIO_InitStruct.Speed = GPIO_SPEED_FREQ_LOW;
  GPIO_InitStruct.Alternate = GPIO_AF13_SAI1;
  HAL_GPIO_Init(GPIOE, &GPIO_InitStruct);

  /*Configure GPIO pin : ARD_D5_Pin */
  GPIO_InitStruct.Pin = ARD_D5_Pin;
  GPIO_InitStruct.Mode = GPIO_MODE_AF_PP;
  GPIO_InitStruct.Pull = GPIO_NOPULL;
  GPIO_InitStruct.Speed = GPIO_SPEED_FREQ_LOW;
  GPIO_InitStruct.Alternate = GPIO_AF2_TIM4;
  HAL_GPIO_Init(ARD_D5_GPIO_Port, &GPIO_InitStruct);

  /*Configure GPIO pins : UART1_RX_Pin UART1_CTS_Pin UART1_RTS_Pin */
  GPIO_InitStruct.Pin = UART1_RX_Pin|UART1_CTS_Pin|UART1_RTS_Pin;
  GPIO_InitStruct.Mode = GPIO_MODE_AF_PP;
  GPIO_InitStruct.Pull = GPIO_NOPULL;
  GPIO_InitStruct.Speed = GPIO_SPEED_FREQ_VERY_HIGH;
  GPIO_InitStruct.Alternate = GPIO_AF7_USART1;
  HAL_GPIO_Init(GPIOG, &GPIO_InitStruct);

  /*Configure GPIO pin : uSD_CMD_Pin */
  GPIO_InitStruct.Pin = uSD_CMD_Pin;
  GPIO_InitStruct.Mode = GPIO_MODE_AF_PP;
  GPIO_InitStruct.Pull = GPIO_NOPULL;
  GPIO_InitStruct.Speed = GPIO_SPEED_FREQ_VERY_HIGH;
  GPIO_InitStruct.Alternate = GPIO_AF12_SDMMC1;
  HAL_GPIO_Init(uSD_CMD_GPIO_Port, &GPIO_InitStruct);

  /*Configure GPIO pins : uSD_D2_Pin uSD_D3_Pin uSD_CLK_Pin uSD_D1_Pin
                           uSD_D0_Pin */
  GPIO_InitStruct.Pin = uSD_D2_Pin|uSD_D3_Pin|uSD_CLK_Pin|uSD_D1_Pin
                          |uSD_D0_Pin;
  GPIO_InitStruct.Mode = GPIO_MODE_AF_PP;
  GPIO_InitStruct.Pull = GPIO_NOPULL;
  GPIO_InitStruct.Speed = GPIO_SPEED_FREQ_VERY_HIGH;
  GPIO_InitStruct.Alternate = GPIO_AF12_SDMMC1;
  HAL_GPIO_Init(GPIOC, &GPIO_InitStruct);

  /*Configure GPIO pin : LCD_TE_Pin */
  GPIO_InitStruct.Pin = LCD_TE_Pin;
  GPIO_InitStruct.Mode = GPIO_MODE_INPUT;
  GPIO_InitStruct.Pull = GPIO_NOPULL;
  HAL_GPIO_Init(LCD_TE_GPIO_Port, &GPIO_InitStruct);

  /*Configure GPIO pins : USB_OTGFS_DP_Pin USB_OTGFS_DM_Pin USB_OTGFS_ID_Pin */
  GPIO_InitStruct.Pin = USB_OTGFS_DP_Pin|USB_OTGFS_DM_Pin|USB_OTGFS_ID_Pin;
  GPIO_InitStruct.Mode = GPIO_MODE_AF_PP;
  GPIO_InitStruct.Pull = GPIO_NOPULL;
  GPIO_InitStruct.Speed = GPIO_SPEED_FREQ_VERY_HIGH;
  GPIO_InitStruct.Alternate = GPIO_AF10_OTG_FS;
  HAL_GPIO_Init(GPIOA, &GPIO_InitStruct);

  /*Configure GPIO pin : DCMI_D6_Pin */
  GPIO_InitStruct.Pin = DCMI_D6_Pin;
  GPIO_InitStruct.Mode = GPIO_MODE_AF_PP;
  GPIO_InitStruct.Pull = GPIO_NOPULL;
  GPIO_InitStruct.Speed = GPIO_SPEED_FREQ_LOW;
  GPIO_InitStruct.Alternate = GPIO_AF10_DCMI;
  HAL_GPIO_Init(DCMI_D6_GPIO_Port, &GPIO_InitStruct);

  /*Configure GPIO pins : MFX_WAKEUP_Pin LCD_PWR_ON_Pin MIC_VDD_Pin */
  GPIO_InitStruct.Pin = MFX_WAKEUP_Pin|LCD_PWR_ON_Pin|MIC_VDD_Pin;
  GPIO_InitStruct.Mode = GPIO_MODE_OUTPUT_PP;
  GPIO_InitStruct.Pull = GPIO_NOPULL;
  GPIO_InitStruct.Speed = GPIO_SPEED_FREQ_LOW;
  HAL_GPIO_Init(GPIOH, &GPIO_InitStruct);

  /*Configure GPIO pin : PF2 */
  GPIO_InitStruct.Pin = GPIO_PIN_2;
  GPIO_InitStruct.Mode = GPIO_MODE_INPUT;
  GPIO_InitStruct.Pull = GPIO_NOPULL;
  HAL_GPIO_Init(GPIOF, &GPIO_InitStruct);

  /*Configure GPIO pins : PSRAM_A1_Pin PSRAM_A0_Pin PSRAM_A3_Pin PSRAM_A4_Pin
                           PSRAM_A5_Pin PSRAM_A9_Pin PSRAM_A8_Pin PSRAM_A7_Pin
                           PSRAM_A6_Pin */
  GPIO_InitStruct.Pin = PSRAM_A1_Pin|PSRAM_A0_Pin|PSRAM_A3_Pin|PSRAM_A4_Pin
                          |PSRAM_A5_Pin|PSRAM_A9_Pin|PSRAM_A8_Pin|PSRAM_A7_Pin
                          |PSRAM_A6_Pin;
  GPIO_InitStruct.Mode = GPIO_MODE_AF_PP;
  GPIO_InitStruct.Pull = GPIO_NOPULL;
  GPIO_InitStruct.Speed = GPIO_SPEED_FREQ_VERY_HIGH;
  GPIO_InitStruct.Alternate = GPIO_AF12_FMC;
  HAL_GPIO_Init(GPIOF, &GPIO_InitStruct);

  /*Configure GPIO pin : Audio_RST_Pin */
  GPIO_InitStruct.Pin = Audio_RST_Pin;
  GPIO_InitStruct.Mode = GPIO_MODE_OUTPUT_PP;
  GPIO_InitStruct.Pull = GPIO_NOPULL;
  GPIO_InitStruct.Speed = GPIO_SPEED_FREQ_LOW;
  HAL_GPIO_Init(Audio_RST_GPIO_Port, &GPIO_InitStruct);

  /*Configure GPIO pin : CTP_INT_Pin */
  GPIO_InitStruct.Pin = CTP_INT_Pin;
  GPIO_InitStruct.Mode = GPIO_MODE_IT_RISING;
  GPIO_InitStruct.Pull = GPIO_NOPULL;
  HAL_GPIO_Init(CTP_INT_GPIO_Port, &GPIO_InitStruct);

  /*Configure GPIO pin : DCMI_CLK_Pin */
  GPIO_InitStruct.Pin = DCMI_CLK_Pin;
  GPIO_InitStruct.Mode = GPIO_MODE_AF_PP;
  GPIO_InitStruct.Pull = GPIO_NOPULL;
  GPIO_InitStruct.Speed = GPIO_SPEED_FREQ_LOW;
  GPIO_InitStruct.Alternate = GPIO_AF14_LPTIM2;
  HAL_GPIO_Init(DCMI_CLK_GPIO_Port, &GPIO_InitStruct);

  /*Configure GPIO pins : DATIN3_Pin DF_CKOUT_Pin */
  GPIO_InitStruct.Pin = DATIN3_Pin|DF_CKOUT_Pin;
  GPIO_InitStruct.Mode = GPIO_MODE_AF_PP;
  GPIO_InitStruct.Pull = GPIO_NOPULL;
  GPIO_InitStruct.Speed = GPIO_SPEED_FREQ_LOW;
  GPIO_InitStruct.Alternate = GPIO_AF6_DFSDM1;
  HAL_GPIO_Init(GPIOC, &GPIO_InitStruct);

  /*Configure GPIO pin : ARD_A3_Pin */
  GPIO_InitStruct.Pin = ARD_A3_Pin;
  GPIO_InitStruct.Mode = GPIO_MODE_ANALOG;
  GPIO_InitStruct.Pull = GPIO_NOPULL;
  HAL_GPIO_Init(ARD_A3_GPIO_Port, &GPIO_InitStruct);

  /*Configure GPIO pins : QSPI_BK1_NCS_Pin QSPI_BK1_IO1_Pin QSPI_BK1_IO0_Pin */
  GPIO_InitStruct.Pin = QSPI_BK1_NCS_Pin|QSPI_BK1_IO1_Pin|QSPI_BK1_IO0_Pin;
  GPIO_InitStruct.Mode = GPIO_MODE_AF_PP;
  GPIO_InitStruct.Pull = GPIO_NOPULL;
  GPIO_InitStruct.Speed = GPIO_SPEED_FREQ_VERY_HIGH;
  GPIO_InitStruct.Alternate = GPIO_AF10_QUADSPI;
  HAL_GPIO_Init(GPIOB, &GPIO_InitStruct);

  /*Configure GPIO pins : ARD_D0_Pin ARD_D1_Pin */
  GPIO_InitStruct.Pin = ARD_D0_Pin|ARD_D1_Pin;
  GPIO_InitStruct.Mode = GPIO_MODE_AF_PP;
  GPIO_InitStruct.Pull = GPIO_NOPULL;
  GPIO_InitStruct.Speed = GPIO_SPEED_FREQ_VERY_HIGH;
  GPIO_InitStruct.Alternate = GPIO_AF8_LPUART1;
  HAL_GPIO_Init(GPIOG, &GPIO_InitStruct);

  /*Configure GPIO pins : ARD_A5_Pin PC1 */
  GPIO_InitStruct.Pin = ARD_A5_Pin|GPIO_PIN_1;
  GPIO_InitStruct.Mode = GPIO_MODE_ANALOG;
  GPIO_InitStruct.Pull = GPIO_NOPULL;
  HAL_GPIO_Init(GPIOC, &GPIO_InitStruct);

  /*Configure GPIO pin : MFX_IRQ_OUT_Pin */
  GPIO_InitStruct.Pin = MFX_IRQ_OUT_Pin;
  GPIO_InitStruct.Mode = GPIO_MODE_IT_RISING;
  GPIO_InitStruct.Pull = GPIO_NOPULL;
  HAL_GPIO_Init(MFX_IRQ_OUT_GPIO_Port, &GPIO_InitStruct);

  /*Configure GPIO pin : I2C2_SCL_Pin */
  GPIO_InitStruct.Pin = I2C2_SCL_Pin;
  GPIO_InitStruct.Mode = GPIO_MODE_AF_OD;
  GPIO_InitStruct.Pull = GPIO_NOPULL;
  GPIO_InitStruct.Speed = GPIO_SPEED_FREQ_VERY_HIGH;
  GPIO_InitStruct.Alternate = GPIO_AF4_I2C2;
  HAL_GPIO_Init(I2C2_SCL_GPIO_Port, &GPIO_InitStruct);

  /*Configure GPIO pins : STMOD_ADC_Pin ARD_A4_Pin */
  GPIO_InitStruct.Pin = STMOD_ADC_Pin|ARD_A4_Pin;
  GPIO_InitStruct.Mode = GPIO_MODE_ANALOG;
  GPIO_InitStruct.Pull = GPIO_NOPULL;
  HAL_GPIO_Init(GPIOA, &GPIO_InitStruct);

  /*Configure GPIO pins : QSPI_BK1_IO2_Pin QSPI_CLK_Pin QSPI_BK1_IO3_Pin */
  GPIO_InitStruct.Pin = QSPI_BK1_IO2_Pin|QSPI_CLK_Pin|QSPI_BK1_IO3_Pin;
  GPIO_InitStruct.Mode = GPIO_MODE_AF_PP;
  GPIO_InitStruct.Pull = GPIO_NOPULL;
  GPIO_InitStruct.Speed = GPIO_SPEED_FREQ_VERY_HIGH;
  GPIO_InitStruct.Alternate = GPIO_AF10_QUADSPI;
  HAL_GPIO_Init(GPIOA, &GPIO_InitStruct);

  /*Configure GPIO pin : JOY_RIGHT_Pin */
  GPIO_InitStruct.Pin = JOY_RIGHT_Pin;
  GPIO_InitStruct.Mode = GPIO_MODE_INPUT;
  GPIO_InitStruct.Pull = GPIO_PULLDOWN;
  HAL_GPIO_Init(JOY_RIGHT_GPIO_Port, &GPIO_InitStruct);

  /*Configure GPIO pin : SPI2_MOSI_Pin */
  GPIO_InitStruct.Pin = SPI2_MOSI_Pin;
  GPIO_InitStruct.Mode = GPIO_MODE_AF_PP;
  GPIO_InitStruct.Pull = GPIO_NOPULL;
  GPIO_InitStruct.Speed = GPIO_SPEED_FREQ_VERY_HIGH;
  GPIO_InitStruct.Alternate = GPIO_AF5_SPI2;
  HAL_GPIO_Init(SPI2_MOSI_GPIO_Port, &GPIO_InitStruct);

  /*Configure GPIO pin : I2C2_SDA_Pin */
  GPIO_InitStruct.Pin = I2C2_SDA_Pin;
  GPIO_InitStruct.Mode = GPIO_MODE_AF_OD;
  GPIO_InitStruct.Pull = GPIO_NOPULL;
  GPIO_InitStruct.Speed = GPIO_SPEED_FREQ_VERY_HIGH;
  GPIO_InitStruct.Alternate = GPIO_AF4_I2C2;
  HAL_GPIO_Init(I2C2_SDA_GPIO_Port, &GPIO_InitStruct);

  /*Configure GPIO pin : STMOD_RESET_Pin */
  GPIO_InitStruct.Pin = STMOD_RESET_Pin;
  GPIO_InitStruct.Mode = GPIO_MODE_INPUT;
  GPIO_InitStruct.Pull = GPIO_NOPULL;
  HAL_GPIO_Init(STMOD_RESET_GPIO_Port, &GPIO_InitStruct);

  /*Configure GPIO pin : SAI1_CKA_Pin */
  GPIO_InitStruct.Pin = SAI1_CKA_Pin;
  GPIO_InitStruct.Mode = GPIO_MODE_AF_PP;
  GPIO_InitStruct.Pull = GPIO_NOPULL;
  GPIO_InitStruct.Speed = GPIO_SPEED_FREQ_LOW;
  GPIO_InitStruct.Alternate = GPIO_AF13_SAI1;
  HAL_GPIO_Init(SAI1_CKA_GPIO_Port, &GPIO_InitStruct);

  /*Configure GPIO pin : DFDATIN1_Pin */
  GPIO_InitStruct.Pin = DFDATIN1_Pin;
  GPIO_InitStruct.Mode = GPIO_MODE_AF_PP;
  GPIO_InitStruct.Pull = GPIO_NOPULL;
  GPIO_InitStruct.Speed = GPIO_SPEED_FREQ_LOW;
  GPIO_InitStruct.Alternate = GPIO_AF6_DFSDM1;
  HAL_GPIO_Init(DFDATIN1_GPIO_Port, &GPIO_InitStruct);

  /*Configure GPIO pin : LED1_Pin */
  GPIO_InitStruct.Pin = LED1_Pin;
  GPIO_InitStruct.Mode = GPIO_MODE_OUTPUT_OD;
  GPIO_InitStruct.Pull = GPIO_NOPULL;
  GPIO_InitStruct.Speed = GPIO_SPEED_FREQ_LOW;
  HAL_GPIO_Init(LED1_GPIO_Port, &GPIO_InitStruct);

}

void Error_Handler(void)
{
  __disable_irq();
  while (1)
  {
  }
}
